# ATSAMC21N17A register map
Vendor: Microchip Technology; Series: SAMC21; File version: 0
CPU: CM0+ r0p0, selectable endian, MPU, no FPU, 2 interrupt priority bits
Registers are 32-bit, read-write, reset 0x0 unless marked. A register's access mark holds for its fields unless they carry their own. Offsets are from the block's base; [hi:lo] are bit positions; {n}, {i} and the like mark numbered series; 'fields as' and 'values as' point back to an identical list.

## DMAC — Direct Memory Access Controller
Base 0x41006000; register names take the prefix DMAC_
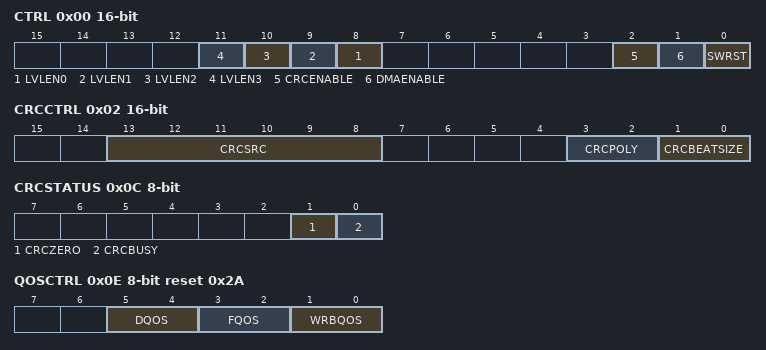
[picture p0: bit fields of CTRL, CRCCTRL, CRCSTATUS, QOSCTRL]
0x00 CTRL 16-bit — Control
  [n+8] LVLEN{n} (n=0..3) — Priority Level {n} Enable
  [2] CRCENABLE
  [1] DMAENABLE
  [0] SWRST — Software Reset
0x02 CRCCTRL 16-bit — CRC Control
  [13:8] CRCSRC — CRC Input Source
    0=NOACT (No action); 1=IO (I/O interface)
  [3:2] CRCPOLY — CRC Polynomial Type
    0=CRC16 (CRC-16 (CRC-CCITT)); 1=CRC32 (CRC32 (IEEE 802.3))
  [1:0] CRCBEATSIZE
    0=BYTE (8-bit bus transfer); 1=HWORD (16-bit bus transfer); 2=WORD (32-bit bus transfer)
0x04 CRCDATAIN — CRC Data Input
0x08 CRCCHKSUM — CRC Checksum
0x0C CRCSTATUS 8-bit
  [1] CRCZERO
  [0] CRCBUSY — CRC Module Busy
0x0D DBGCTRL 8-bit — Debug Control
  [0] DBGRUN — Debug Run
0x0E QOSCTRL 8-bit reset 0x2A — QOS Control
  [all] fields
    0=DISABLE (Background (no sensitive operation)); 1=LOW (Sensitive Bandwidth); 2=MEDIUM (Sensitive Latency); 3=HIGH (Critical Latency)
  [5:4] DQOS — Data Transfer Quality of Service
  [3:2] FQOS — Fetch Quality of Service
  [1:0] WRBQOS — Write-Back Quality of Service
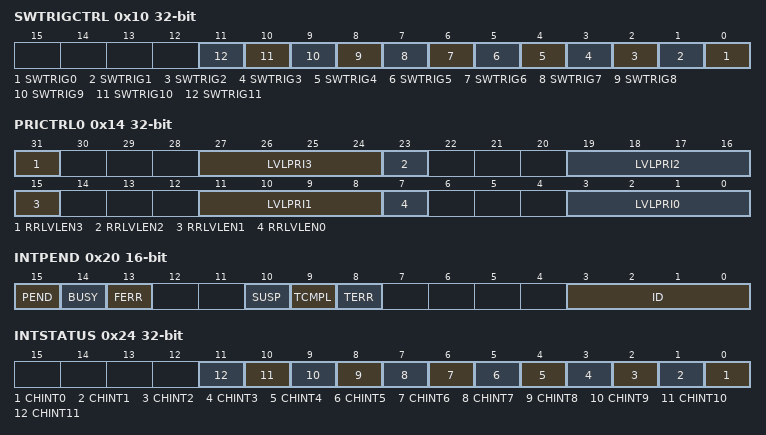
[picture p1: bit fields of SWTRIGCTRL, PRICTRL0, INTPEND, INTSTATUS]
0x10 SWTRIGCTRL — Software Trigger Control
  [n] SWTRIG{n} (n=0..11) — Channel {n} Software Trigger
0x14 PRICTRL0 — Priority Control 0
  [31] RRLVLEN3 — Level 3 Round-Robin Scheduling Enable
  [8n+3:8n] LVLPRI{n} (n=0..3) — Level {n} Channel Priority Number
  [23] RRLVLEN2 — Level 2 Round-Robin Scheduling Enable
  [15] RRLVLEN1 — Level 1 Round-Robin Scheduling Enable
  [7] RRLVLEN0 — Level 0 Round-Robin Scheduling Enable
    0=STATIC_LVL (Static arbitration scheme for channels with level 3 priority); 1=ROUND_ROBIN_LVL (Round-robin arbitration scheme for channels with level 3 priority)
0x20 INTPEND 16-bit — Interrupt Pending
  [15] PEND — Pending
  [14] BUSY
  [13] FERR — Fetch Error
  [10] SUSP — Channel Suspend
  [9] TCMPL — Transfer Complete
  [8] TERR — Transfer Error
  [3:0] ID — Channel ID
0x24 INTSTATUS ro — Interrupt Status
  [n] CHINT{n} (n=0..11) — Channel {n} Pending Interrupt
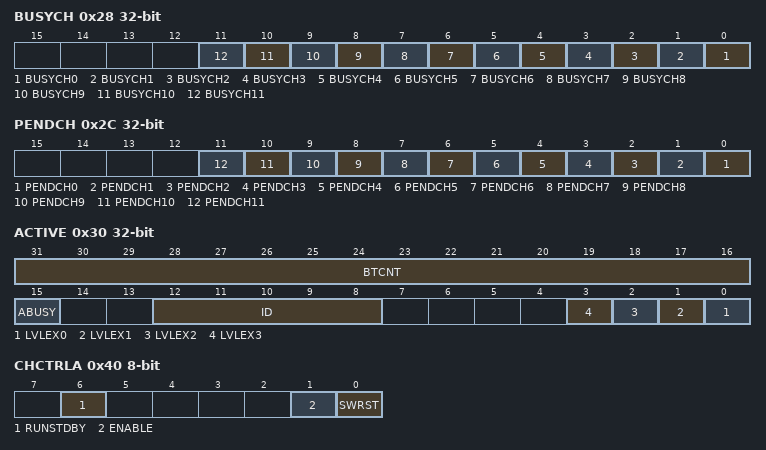
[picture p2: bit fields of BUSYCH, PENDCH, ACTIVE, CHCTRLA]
0x28 BUSYCH ro — Busy Channels
  [n] BUSYCH{n} (n=0..11) — Busy Channel {n}
0x2C PENDCH ro — Pending Channels
  [n] PENDCH{n} (n=0..11) — Pending Channel {n}
0x30 ACTIVE ro — Active Channel and Levels
  [31:16] BTCNT — Active Channel Block Transfer Count
  [15] ABUSY — Active Channel Busy
  [12:8] ID — Active Channel ID
  [n] LVLEX{n} (n=0..3) — Level {n} Channel Trigger Request Executing
0x34 BASEADDR — Descriptor Memory Section Base Address
  [31:0] BASEADDR — Descriptor Memory Base Address
0x38 WRBADDR — Write-Back Memory Section Base Address
  [31:0] WRBADDR — Write-Back Memory Base Address
0x3F CHID 8-bit — Channel ID
  [3:0] ID
0x40 CHCTRLA 8-bit — Channel Control A
  [6] RUNSTDBY — Channel run in standby
  [1] ENABLE — Channel Enable
  [0] SWRST — Channel Software Reset
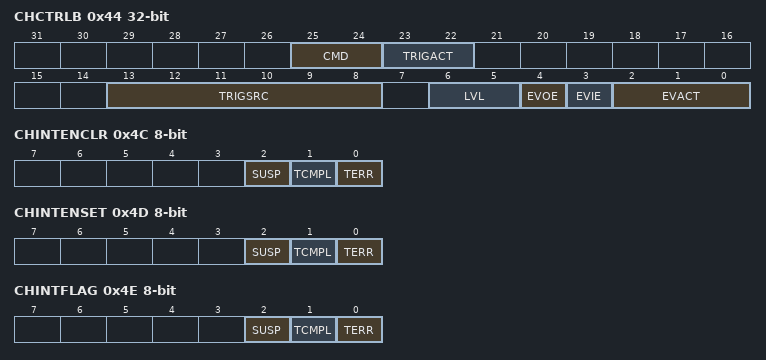
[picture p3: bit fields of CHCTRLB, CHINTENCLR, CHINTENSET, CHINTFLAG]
0x44 CHCTRLB — Channel Control B
  [25:24] CMD — Software Command
    0=NOACT (No action); 1=SUSPEND (Channel suspend operation); 2=RESUME (Channel resume operation)
  [23:22] TRIGACT — Trigger Action
    0=BLOCK (One trigger required for each block transfer); 2=BEAT (One trigger required for each beat transfer); 3=TRANSACTION (One trigger required for each transaction)
  [13:8] TRIGSRC — Trigger Source
    0=DISABLE (Only software/event triggers); 1=TSENS (TSENS Result Ready Trigger); 2=SERCOM0_RX (SERCOM0 RX Trigger); 3=SERCOM0_TX (SERCOM0 TX Trigger); 4=SERCOM1_RX (SERCOM1 RX Trigger); 5=SERCOM1_TX (SERCOM1 TX Trigger); 6=SERCOM2_RX (SERCOM2 RX Trigger); 7=SERCOM2_TX (SERCOM2 TX Trigger); 8=SERCOM3_RX (SERCOM3 RX Trigger); 9=SERCOM3_TX (SERCOM3 TX Trigger); 10=SERCOM4_RX (SERCOM4 RX Trigger); 11=SERCOM4_TX (SERCOM4 TX Trigger); 12=SERCOM5_RX (SERCOM5 RX Trigger); 13=SERCOM5_TX (SERCOM5 TX Trigger); 14=CAN0_DEBUG (CAN0 Debug Trigger Reserved); 15=CAN1_DEBUG (CAN1 Debug Trigger Reserved); 16=TCC0_OVF (TCC0 Overflow Trigger); {v}=TCC0_MC{v-17} (TCC0 Match/Compare {v-17} Trigger) (v=17..20); 21=TCC1_OVF (TCC1 Overflow Trigger); 22=TCC1_MC0 (TCC1 Match/Compare 0 Trigger); 23=TCC1_MC1 (TCC1 Match/Compare 1 Trigger); 24=TCC2_OVF (TCC2 Overflow Trigger); 25=TCC2_MC0 (TCC2 Match/Compare 0 Trigger); 26=TCC2_MC1 (TCC2 Match/Compare 1 Trigger); 27=TC0_OVF (TC0 Overflow Trigger); 28=TC0_MC0 (TC0 Match/Compare 0 Trigger); 29=TC0_MC1 (TC0 Match/Compare 1 Trigger); 30=TC1_OVF (TC1 Overflow Trigger); 31=TC1_MC0 (TC1 Match/Compare 0 Trigger); 32=TC1_MC1 (TC1 Match/Compare 1 Trigger); 33=TC2_OVF (TC2 Overflow Trigger); 34=TC2_MC0 (TC2 Match/Compare 0 Trigger); 35=TC2_MC1 (TC2 Match/Compare 1 Trigger); 36=TC3_OVF (TC3 Overflow Trigger); 37=TC3_MC0 (TC3 Match/Compare 0 Trigger); 38=TC3_MC1 (TC3 Match/Compare 1 Trigger); 39=TC4_OVF (TC4 Overflow Trigger); 40=TC4_MC0 (TC4 Match/Compare 0 Trigger); 41=TC4_MC1 (TC4 Match/Compare 1 Trigger); 42=ADC0_RESRDY (ADC0 Result Ready Trigger); 43=ADC1_RESRDY (ADC1 Result Ready Trigger); 44=SDADC_RESRDY (SDADC Result Ready Trigger); 45=DAC_EMPTY (DAC Empty Trigger); 46=PTC_EOC (PTC End of Conversion Trigger); 47=PTC_WCOMP (PTC Window Compare Trigger); 48=PTC_SEQ (PTC Sequence Trigger); 49=SERCOM6_RX (SERCOM6 RX Trigger); 50=SERCOM6_TX (SERCOM6 TX Trigger); 51=SERCOM7_RX (SERCOM7 RX Trigger); 52=SERCOM7_TX (SERCOM7 TX Trigger); 53=TC5_OVF (TC5 Overflow Trigger); 54=TC5_MC0 (TC5 Match/Compare 0 Trigger); 55=TC5_MC1 (TC5 Match/Compare 1 Trigger); 56=TC6_OVF (TC6 Overflow Trigger); 57=TC6_MC0 (TC6 Match/Compare 0 Trigger); 58=TC6_MC1 (TC6 Match/Compare 1 Trigger); 59=TC7_OVF (TC7 Overflow Trigger); 60=TC7_MC0 (TC7 Match/Compare 0 Trigger); 61=TC7_MC1 (TC7 Match/Compare 1 Trigger)
  [6:5] LVL — Channel Arbitration Level
    {v}=Channel Priority Level {v} (v=0..3)
  [4] EVOE — Channel Event Output Enable
  [3] EVIE — Channel Event Input Enable
  [2:0] EVACT — Event Input Action
    0=NOACT (No action); 1=TRIG (Transfer and periodic transfer trigger); 2=CTRIG (Conditional transfer trigger); 3=CBLOCK (Conditional block transfer); 4=SUSPEND (Channel suspend operation); 5=RESUME (Channel resume operation); 6=SSKIP (Skip next block suspend action)
0x4C CHINTENCLR 8-bit — Channel Interrupt Enable Clear
  [2] SUSP — Channel Suspend Interrupt Enable
  [1] TCMPL — Channel Transfer Complete Interrupt Enable
  [0] TERR — Channel Transfer Error Interrupt Enable
0x4D CHINTENSET 8-bit — Channel Interrupt Enable Set
  fields as CHINTENCLR
0x4E CHINTFLAG 8-bit — Channel Interrupt Flag Status and Clear
  [2] SUSP — Channel Suspend
  [1] TCMPL — Channel Transfer Complete
  [0] TERR — Channel Transfer Error
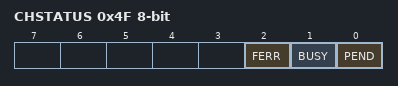
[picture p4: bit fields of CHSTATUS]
0x4F CHSTATUS 8-bit ro — Channel Status
  [2] FERR — Channel Fetch Error
  [1] BUSY — Channel Busy
  [0] PEND — Channel Pending

## Notices in the file
Copyright (c) 2017 Microchip Technology Inc.
SPDX-License-Identifier: Apache-2.0
Licensed under the Apache License, Version 2.0 (the "License");
you may not use this file except in compliance with the License.
You may obtain a copy of the License at
http://www.apache.org/licenses/LICENSE-2.0
Unless required by applicable law or agreed to in writing, software
distributed under the License is distributed on an "AS IS" BASIS,
WITHOUT WARRANTIES OR CONDITIONS OF ANY KIND, either express or implied.
See the License for the specific language governing permissions and
limitations under the License.
